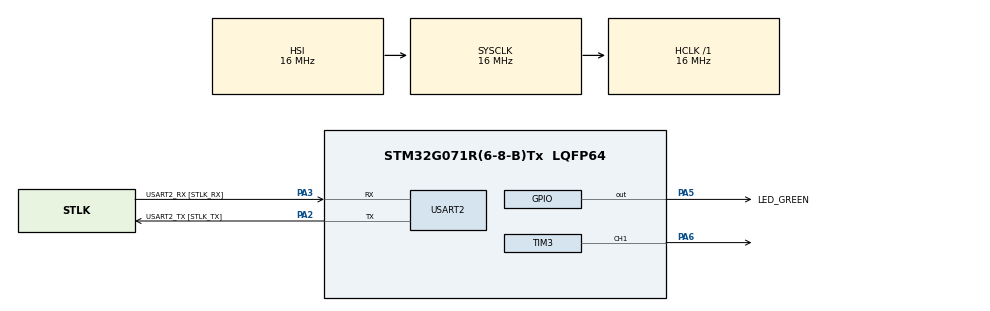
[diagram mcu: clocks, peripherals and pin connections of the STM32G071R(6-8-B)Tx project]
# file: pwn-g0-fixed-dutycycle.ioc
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Dma.Request0=TIM3_CH1
Dma.TIM3_CH1.0.Direction=DMA_MEMORY_TO_PERIPH
Dma.TIM3_CH1.0.EventEnable=DISABLE
Dma.TIM3_CH1.0.Instance=DMA1_Channel1
Dma.TIM3_CH1.0.MemDataAlignment=DMA_MDATAALIGN_HALFWORD
Dma.TIM3_CH1.0.MemInc=DMA_MINC_ENABLE
Dma.TIM3_CH1.0.Mode=DMA_CIRCULAR
Dma.TIM3_CH1.0.PeriphDataAlignment=DMA_PDATAALIGN_HALFWORD
Dma.TIM3_CH1.0.PeriphInc=DMA_PINC_DISABLE
Dma.TIM3_CH1.0.Polarity=HAL_DMAMUX_REQ_GEN_RISING
Dma.TIM3_CH1.0.Priority=DMA_PRIORITY_LOW
Dma.TIM3_CH1.0.RequestNumber=1
Dma.TIM3_CH1.0.SignalID=NONE
Dma.TIM3_CH1.0.SyncEnable=DISABLE
Dma.TIM3_CH1.0.SyncPolarity=HAL_DMAMUX_SYNC_NO_EVENT
Dma.TIM3_CH1.0.SyncRequestNumber=1
Dma.TIM3_CH1.0.SyncSignalID=NONE
Mcu.Family=STM32G0
Mcu.Name=STM32G071R(6-8-B)Tx
Mcu.Package=LQFP64
NVIC.DMA1_Channel1_IRQn=true\:0\:0\:false\:false\:true\:false\:true\:true
NVIC.TIM3_IRQn=true\:0\:0\:false\:false\:true\:true\:true\:true
PA13.GPIO_Label=TMS
PA13.Mode=Serial_Wire
PA13.Signal=SYS_SWDIO
PA14-BOOT0.GPIO_Label=TCK
PA14-BOOT0.Mode=Serial_Wire
PA14-BOOT0.Signal=SYS_SWCLK
PA2.GPIO_Label=USART2_TX [STLK_TX]
PA2.GPIO_PuPd=GPIO_PULLUP
PA2.Mode=Asynchronous
PA2.Signal=USART2_TX
PA3.GPIO_Label=USART2_RX [STLK_RX]
PA3.GPIO_PuPd=GPIO_PULLUP
PA3.Mode=Asynchronous
PA3.Signal=USART2_RX
PA5.GPIO_Label=LED_GREEN
PA5.GPIO_Speed=GPIO_SPEED_FREQ_HIGH
PA5.Signal=GPIO_Output
PA6.Signal=S_TIM3_CH1
PC13.Mode=SYS_WakeUp1
PC13.Signal=SYS_WKUP2
PC14-OSC32_IN\ (PC14).Mode=LSE-External-Oscillator
PC14-OSC32_IN\ (PC14).Signal=RCC_OSC32_IN
PC15-OSC32_OUT\ (PC15).Mode=LSE-External-Oscillator
PC15-OSC32_OUT\ (PC15).Signal=RCC_OSC32_OUT
PF0-OSC_IN\ (PF0).GPIO_Label=MCO
PF0-OSC_IN\ (PF0).Mode=HSE-External-Clock-Source
PF0-OSC_IN\ (PF0).Signal=RCC_OSC_IN
ProjectManager.HeapSize=0x200
ProjectManager.StackSize=0x400
ProjectManager.TargetToolchain=STM32CubeIDE
RCC.AHBFreq_Value=16000000
RCC.CortexFreq_Value=16000000
RCC.EXTERNAL_CLOCK_VALUE=12288000
RCC.HCLKFreq_Value=16000000
RCC.HSE_VALUE=8000000
RCC.HSI_VALUE=16000000
RCC.SYSCLKFreq_VALUE=16000000
RCC.VCOOutputFreq_Value=128000000
SH.S_TIM3_CH1.0=TIM3_CH1,PWM Generation1 CH1
TIM3.Channel-PWM\ Generation1\ CH1=TIM_CHANNEL_1
TIM3.Period=1599
TIM3.Prescaler=0
TIM3.Pulse-PWM\ Generation1\ CH1=240
USART2.VirtualMode-Asynchronous=VM_ASYNC
VP_TIM3_VS_ClockSourceINT.Mode=Internal
board=NUCLEO-G071RB

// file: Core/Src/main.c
/* USER CODE BEGIN Header */
/**
  ******************************************************************************
  * @file           : main.c
  * @brief          : Main program body
  ******************************************************************************
  * @attention
  *
  * Copyright (c) 2022 STMicroelectronics.
  * All rights reserved.
  *
  * This software is licensed under terms that can be found in the LICENSE file
  * in the root directory of this software component.
  * If no LICENSE file comes with this software, it is provided AS-IS.
  *
  ******************************************************************************
  */

/**
 * shows how to implement the pwm in both dma and the timer interrupt. timer interrupt is commented.
 */
/* USER CODE END Header */
#include "main.h"
#include "dma.h"
#include "tim.h"
#include "usart.h"
#include "gpio.h"

void SystemClock_Config(void);

/* USER CODE BEGIN 0 */
uint16_t dutyCycle[] = {240,480,720,960,1200,1440};
uint16_t arr = 0;
uint16_t arrCount =  sizeof(dutyCycle)/sizeof(dutyCycle[0]);
/* USER CODE END 0 */

int main(void)
{

  /* MCU Configuration--------------------------------------------------------*/

  /* Reset of all peripherals, Initializes the Flash interface and the Systick. */
  HAL_Init();

  /* Configure the system clock */
  SystemClock_Config();

  /* Initialize all configured peripherals */
  MX_GPIO_Init();
  MX_DMA_Init();
  MX_TIM3_Init();
  MX_USART2_UART_Init();
  /* USER CODE BEGIN 2 */
//  HAL_TIM_PWM_Start_IT(&htim3,TIM_CHANNEL_1);
  arr = __HAL_TIM_GET_AUTORELOAD(&htim3);
  HAL_TIM_PWM_Start_DMA(&htim3,TIM_CHANNEL_1,(uint32_t*)&dutyCycle,arrCount);

  /* USER CODE END 2 */

  /* Infinite loop */
  while (1)
  {

  }
}

void SystemClock_Config(void)
{
  RCC_OscInitTypeDef RCC_OscInitStruct = {0};
  RCC_ClkInitTypeDef RCC_ClkInitStruct = {0};

  /** Configure the main internal regulator output voltage
  */
  HAL_PWREx_ControlVoltageScaling(PWR_REGULATOR_VOLTAGE_SCALE1);

  /** Initializes the RCC Oscillators according to the specified parameters
  * in the RCC_OscInitTypeDef structure.
  */
  RCC_OscInitStruct.OscillatorType = RCC_OSCILLATORTYPE_HSI;
  RCC_OscInitStruct.HSIState = RCC_HSI_ON;
  RCC_OscInitStruct.HSIDiv = RCC_HSI_DIV1;
  RCC_OscInitStruct.HSICalibrationValue = RCC_HSICALIBRATION_DEFAULT;
  RCC_OscInitStruct.PLL.PLLState = RCC_PLL_NONE;
  if (HAL_RCC_OscConfig(&RCC_OscInitStruct) != HAL_OK)
  {
    Error_Handler();
  }

  /** Initializes the CPU, AHB and APB buses clocks
  */
  RCC_ClkInitStruct.ClockType = RCC_CLOCKTYPE_HCLK|RCC_CLOCKTYPE_SYSCLK
                              |RCC_CLOCKTYPE_PCLK1;
  RCC_ClkInitStruct.SYSCLKSource = RCC_SYSCLKSOURCE_HSI;
  RCC_ClkInitStruct.AHBCLKDivider = RCC_SYSCLK_DIV1;
  RCC_ClkInitStruct.APB1CLKDivider = RCC_HCLK_DIV1;

  if (HAL_RCC_ClockConfig(&RCC_ClkInitStruct, FLASH_LATENCY_0) != HAL_OK)
  {
    Error_Handler();
  }
}

/* USER CODE BEGIN 4 */
/**
 * the below call back will arises in both interrupt and the dma mode. The differenct between is, in the interrupt mode it will fire when the compare register value is
 * equal to the ARR (auto reload register value) while in DMA mode it will fire when all the values provided in the memory are exausted.
 */
void HAL_TIM_PWM_PulseFinishedCallback(TIM_HandleTypeDef *htim)
{
	// uncommen below code when working in the interrupt mode
//	dutyCycle = HAL_TIM_ReadCapturedValue(&htim3,TIM_CHANNEL_1);
//	dutyCycle = dutyCycle + 16;
//	uint16_t arr =  __HAL_TIM_GET_AUTORELOAD(&htim3);
//	if(dutyCycle <arr)
//	{
//		__HAL_TIM_SET_COMPARE(&htim3, TIM_CHANNEL_1,dutyCycle);
//	}
//	else
//		__HAL_TIM_SET_COMPARE(&htim3, TIM_CHANNEL_1,120);

	// dma mode logic

}

// half complete callback

void HAL_TIM_PWM_PulseFinishedHalfCpltCallback(TIM_HandleTypeDef *htim){

	/**
	 * since first half is completed, now we can manuplate it
	 */

}

/* USER CODE END 4 */

void Error_Handler(void)
{
  __disable_irq();
  while (1)
  {
  }
}
